# NAVSS0_PVU0_CFG register map
Vendor: Texas Instruments
Peripheral module from a debugger description file (folder am65x).
Registers are 32-bit, read-only, reset values left out (the file's numbers can be read two ways) unless marked. A register's access mark holds for its fields unless they carry their own. Offsets are as the file gives them; lines under a group give offsets from that group; [hi:lo] are bit positions; {n}, {i} and the like mark numbered series; 'fields as' and 'values as' point back to an identical list; <NAME> marks a mode.

## NAVSS0_PVU0_CFG
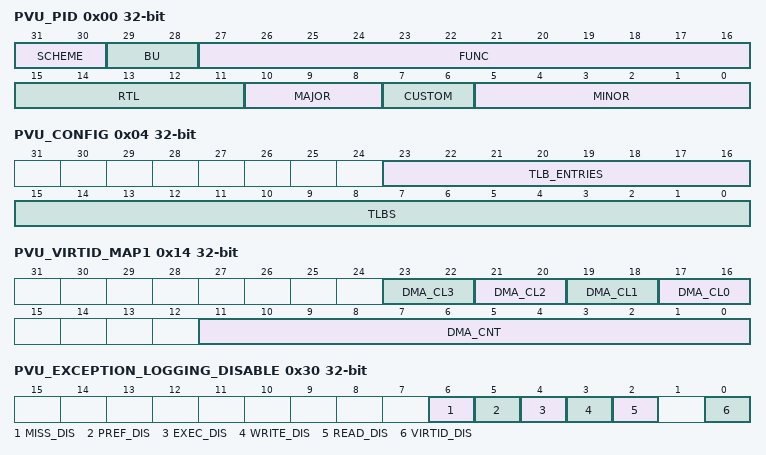
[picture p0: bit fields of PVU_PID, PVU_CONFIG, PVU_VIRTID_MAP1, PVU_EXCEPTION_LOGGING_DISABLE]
0x00 PVU_PID — The Revision Register contains the major and minor revisions for the module.
  [31:30] SCHEME — PID register scheme
  [29:28] BU
  [27:16] FUNC — Module ID
  [15:11] RTL — RTL revision.9h - SR1.0, Fh - SR2.0 in this device.
  [10:8] MAJOR — Major revision
  [7:6] CUSTOM
  [5:0] MINOR — Minor revision
0x04 PVU_CONFIG — The Config Register contains the configuration values for the module.
  [23:16] TLB_ENTRIES — Number of TLB entries per channel
  [15:0] TLBS — Number of TLBs100h
0x10 PVU_ENABLE rw — The Enable Register enables the PVU0.
  [0] EN — PVU0 Enable bit. 0 = disabled. 1 = enabled
0x14 PVU_VIRTID_MAP1 rw — The Map Register 1 defines the virtid mapping for the PVU0.
  [2n+17:2n+16] DMA_CL{n} (n=0..3) — Map for DMA sub-class {n}. Value is the final sub-class and selects TLB+n.
  [11:0] DMA_CNT — VirtID count for DMA class that use sub-classes.
0x18 PVU_VIRTID_MAP2 rw — The Map Register 2 defines the virtid mapping for the PVU0.
  [11:0] MAX_CNT — VirtID maximum for PVU0.
0x30 PVU_EXCEPTION_LOGGING_DISABLE rw — The Exception Logging Disable Register defines which types of faults are disabled for logging.
  [6] MISS_DIS — Disable for PVU0 miss fault logging. 0 = enable miss fault logging. 1 = disable miss fault logging.
  [5] PREF_DIS — Disable for prefetch permissions fault logging. 0 = enable prefetch fault logging. 1 = disable prefetch fault logging.
  [4] EXEC_DIS — Disable for execute permissions fault logging. 0 = enable execute fault logging. 1 = disable execute fault logging.
  [3] WRITE_DIS — Disable for write permissions fault logging. 0 = enable write fault logging. 1 = disable write fault logging.
  [2] READ_DIS — Disable for read permissions fault logging. 0 = enable read fault logging. 1 = disable read fault logging.
  [0] VIRTID_DIS — Disable for virtID permission fault logging. 0 = enable virtID fault logging. 1 = disable virtID fault logging.
0x104 PVU_DESTINATION_ID rw — The Destination ID Register defines the destination ID value for error messages.
  [7:0] DEST_ID — The destination ID.
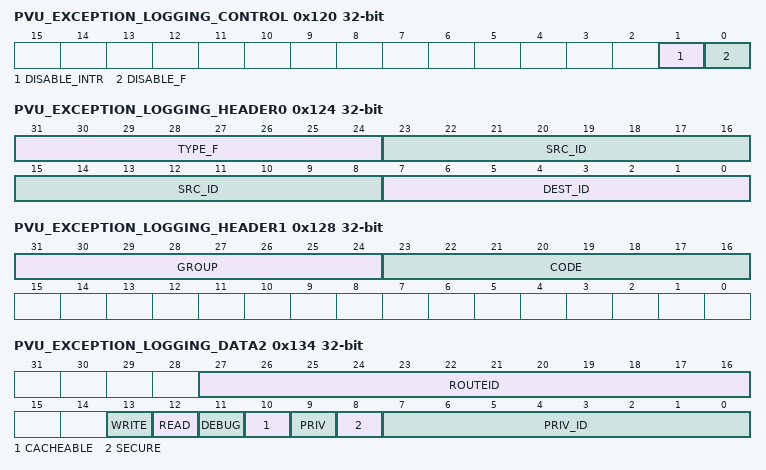
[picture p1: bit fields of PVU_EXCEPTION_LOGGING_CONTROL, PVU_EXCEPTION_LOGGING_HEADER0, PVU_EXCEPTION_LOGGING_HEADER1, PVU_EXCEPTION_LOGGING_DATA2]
0x120 PVU_EXCEPTION_LOGGING_CONTROL rw — The Exception Logging Control Register controls the exception logging.
  [1] DISABLE_INTR — Disables logging interrupt when set. This will not disable logging, so if cleared the current log should also be cleared to guarantee the next log generates the interrupt.
  [0] DISABLE_F — Disables logging when set. This will also disable interrupts.
0x124 PVU_EXCEPTION_LOGGING_HEADER0 — The Exception Logging Header 0 Register contains the first word of the header.
  [31:24] TYPE_F — Type. 6 = PVU0.
  [23:8] SRC_ID — Source ID.
  [7:0] DEST_ID — Destination ID.
0x128 PVU_EXCEPTION_LOGGING_HEADER1 — The Exception Logging Header 1 Register contains the second word of the header.
  [31:24] GROUP
  [23:16] CODE — Code. 0 = PVU0 miss. 1 = Max virtid violation. 2 = reserved. 3 = read permission violation. 4 = write permission violation. 5 = execute permission violation. 6 = prefetch permission violation.
0x12C PVU_EXCEPTION_LOGGING_DATA0 — The Exception Logging Data 0 Register contains the first word of the data.
  [31:0] ADDR_L — Input virtual address lower 32 bits.
0x130 PVU_EXCEPTION_LOGGING_DATA1 — The Exception Logging Data 1 Register contains the second word of the data.
  [15:0] ADDR_H — Input virtual address upper 12 bits.
0x134 PVU_EXCEPTION_LOGGING_DATA2 — The Exception Logging Data 2 Register contains the third word of the data.
  [27:16] ROUTEID, [13] WRITE, [12] READ, [11] DEBUG, [10] CACHEABLE, [9] PRIV, [8] SECURE, [7:0] PRIV_ID
0x138 PVU_EXCEPTION_LOGGING_DATA3 — The Exception Logging Data 3 Register contains the third word of the data. Reading this register will clear the error pending bit except when emudbg is set.
  [9:0] BYTECNT — Byte count.
0x140 PVU_EXCEPTION_PEND_SET access not given — The Exception Logging Interrupt Pending Set Register allows to set the pend signal.
  [0] PEND_SET — Write a 1 to set the exception pend signal. (access RW1S)
0x144 PVU_EXCEPTION_PEND_CLEAR access not given — The Exception Logging Interrupt Pending Clear Register allows to clear the pend signal.
  [0] PEND_CLR — Write a 1 to clear the exception pend signal. (access RW1C)
0x148 PVU_EXCEPTION_ENABLE_SET access not given — The Exception Logging Interrupt Enable Set Register allows to set the interrupt enable signal.
  [0] ENABLE_SET — Write a 1 to set the exception interrupt enable signal. (access RW1S)
0x14C PVU_EXCEPTION_ENABLE_CLEAR access not given — The Exception Logging Interrupt Enable Clear Register allows to clear the interrupt enable signal.
  [0] ENABLE_CLR — Write a 1 to clear the exception interrupt enable signal. (access RW1C)
0x150 PVU_EOI_REG access per field — EOI Register The EOI register is used to re-trigger the pulse interrupt signal to ensure that any nested interrupt events are serviced. The software interrupt handler must write to the EOI register at the end of the current interrupt processing routine, so that new events can re-trigger the pulse interrupt signal again. For level interrupt signals the EOI register is not functional and must not be used.
  [15:0] EOI_WR rw — EOI Register
